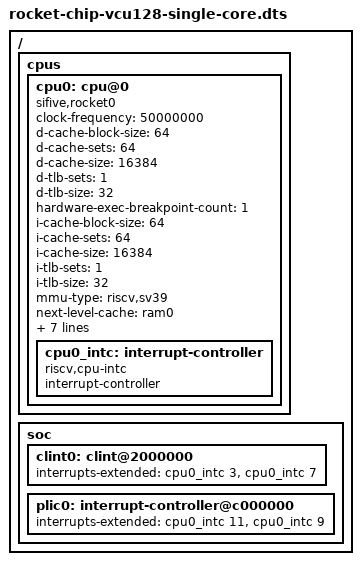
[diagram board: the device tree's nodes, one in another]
#include "rocket-chip-vcu128.dtsi"

/ {
	cpus {
		cpu0: cpu@0 {
			clock-frequency = <50000000>;
			compatible = "sifive,rocket0", "riscv";
			d-cache-block-size = <64>;
			d-cache-sets = <64>;
			d-cache-size = <16384>;
			d-tlb-sets = <1>;
			d-tlb-size = <32>;
			device_type = "cpu";
			hardware-exec-breakpoint-count = <1>;
			i-cache-block-size = <64>;
			i-cache-sets = <64>;
			i-cache-size = <16384>;
			i-tlb-sets = <1>;
			i-tlb-size = <32>;
			mmu-type = "riscv,sv39";
			next-level-cache = <&ram0>;
			reg = <0x0>;
			riscv,isa = "rv64imafdcbzicsr_zifencei_zihpm_zfh_zba_zbb_zbs_xrocket";
			riscv,pmpgranularity = <4>;
			riscv,pmpregions = <8>;
			status = "okay";
			timebase-frequency = <500000>;
			tlb-split;
			cpu0_intc: interrupt-controller {
				#interrupt-cells = <1>;
				compatible = "riscv,cpu-intc";
				interrupt-controller;
			};
		};
	};
	soc {
		clint0: clint@2000000 {
			interrupts-extended = <&cpu0_intc 3 &cpu0_intc 7>;
		};
		plic0: interrupt-controller@c000000 {
			interrupts-extended = <&cpu0_intc 11 &cpu0_intc 9>;
		};
	};
};
